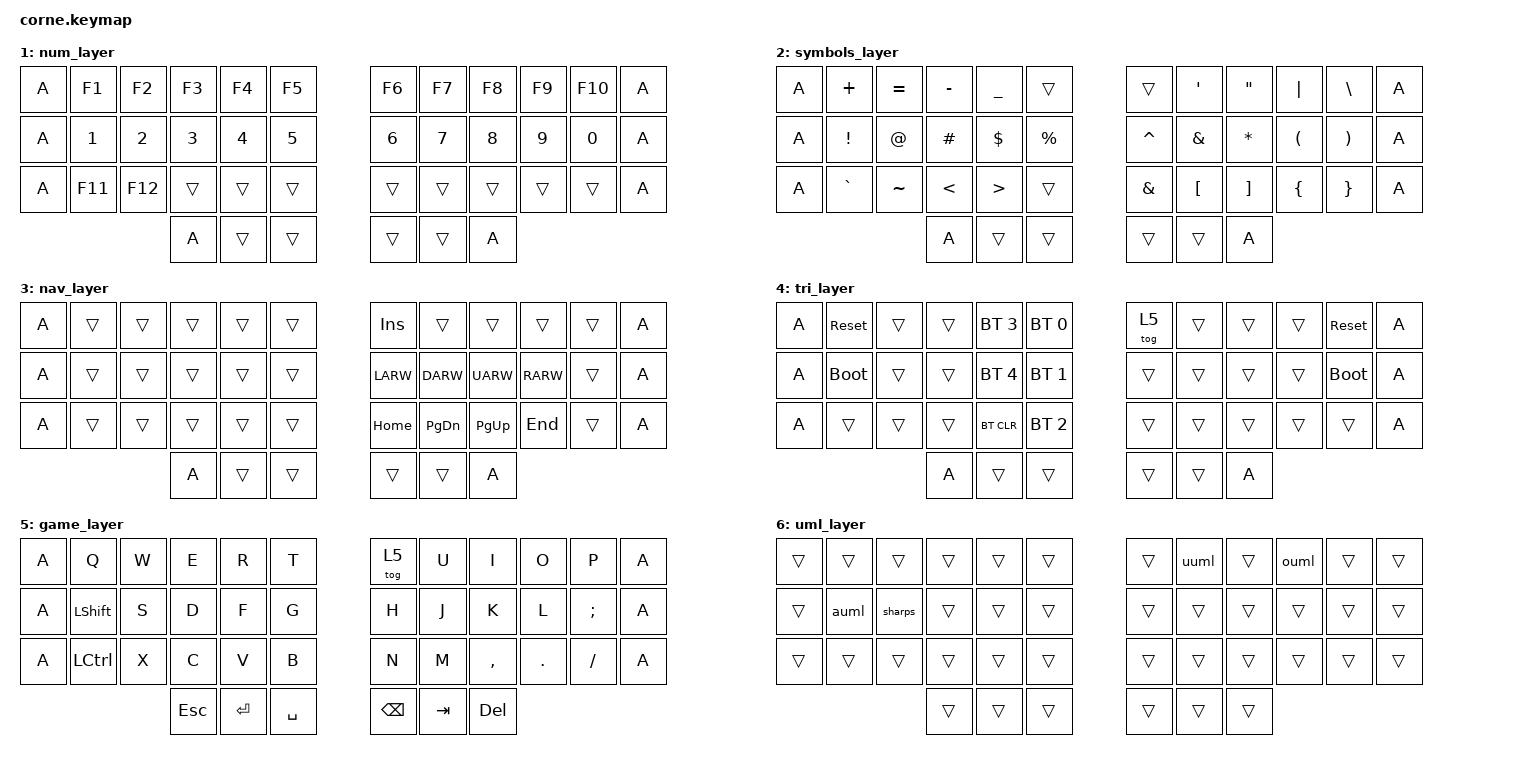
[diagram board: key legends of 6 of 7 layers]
// Copyright (c) 2022 The ZMK Contributors
// SPDX-License-Identifier: MIT

#include <behaviors.dtsi>
#include <dt-bindings/zmk/keys.h>
#include <dt-bindings/zmk/bt.h>

// Home row mods macro
#define HRML(k1,k2,k3,k4) &ht LSHFT k1  &ht LCTRL k2  &ht LGUI k3  &ht LALT k4
#define HRMR(k1,k2,k3,k4) &ht RALT k1  &ht RGUI k2  &ht RCTRL k3  &ht RSHFT k4

// combo macro
#define COMBO(name, pos, bind) name { timeout-ms = <30>; key-positions = pos ; bindings = bind ; };

/ {
    macros {
        auml: auml {
            compatible = "zmk,behavior-macro";
            #binding-cells = <0>;
            bindings = <&macro_tap &kp RALT &kp A &kp DQT> ;
        };
        uuml: uuml {
            compatible = "zmk,behavior-macro";
            #binding-cells = <0>;
            bindings = <&macro_tap &kp RALT &kp U &kp DQT> ;
        };
        ouml: ouml {
            compatible = "zmk,behavior-macro";
            #binding-cells = <0>;
            bindings = <&macro_tap &kp RALT &kp O &kp DQT> ;
        };
        sharps: sharps {
            compatible = "zmk,behavior-macro";
            #binding-cells = <0>;
            bindings = <&macro_tap &kp RALT &kp S &kp S> ;
        };
    };

    behaviors {
        ht: hold_tap {
            label = "hold_tap";
            compatible = "zmk,behavior-hold-tap";
            #binding-cells = <2>;
            flavor = "balanced";
            tapping-term-ms = <220>;
            quick-tap-ms = <150>;
            #global-quick-tap;
            bindings = <&kp>, <&kp>;
        };
    };

    conditional_layers {
        compatible = "zmk,conditional-layers";
        tri_layer {
            if-layers = <1 2>;
            then-layer = <4>;
        };
    };

    combos {
        compatible = "zmk,combos";

        COMBO(combo_caps,  <13 22>, <&caps_word>)

        COMBO(combo_lt,    <2  3 >, <&kp LT>)
        COMBO(combo_lbkt,  <3  4 >, <&kp LBKT>)
        COMBO(combo_rbkt,  <7  8 >, <&kp RBKT>)
        COMBO(combo_gt,    <8  9 >, <&kp GT>)
        COMBO(combo_lbrc,  <14 15>, <&kp LBRC>)
        COMBO(combo_lpar,  <15 16>, <&kp LPAR>)
        COMBO(combo_rpar,  <19 20>, <&kp RPAR>)
        COMBO(combo_rbrc,  <20 21>, <&kp RBRC>)

    };

    keymap {
        compatible = "zmk,keymap";
        default_layer {
            bindings = <
        //╭────1─────┬────2─────┬────3─────┬────4─────┬────5─────╮   ╭────6─────┬────7─────┬────8─────┬────9─────┬────10────╮
        //│  Q       │  W       │  E       │  R       │  T       │   │  Y       │  U       │  I       │  O       │  P       │
&kp A       &kp Q      &kp W      &kp E      &kp R      &kp T          &kp Y      &kp U      &kp I      &kp O      &kp P        &kp A
        //├───13─────┼────14────┼────15────┼────16────┼────17────┤   ├────18────┼────19────┼────20────┼────21────┼────22────┤
        //│  A       │  S       │  D       │  F       │  G       │   │  H       │  J       │  K       │  L       │  : ;     │
&kp A       HRML(A,        S,         D,         F)     &kp G          &kp H      HRMR(J,        K,         L,      SEMI)        &kp A
        //├────25────┼────26────┼────27────┼────28────┼────29────┤   ├────30────┼────31────┼────32────┼────33────┼────34────┤
        //│  Z       │  X       │  C       │  V       │  B       │   │  N       │  M       │ , <      │ . >      │ / ?      │
&kp A       &kp Z      &kp X      &kp C      &kp V      &kp B          &kp N      &kp M      &kp COMMA  &kp DOT    &kp FSLH        &kp A
        //╰──────────┴──────────┴──────────┼──────────┼──────────┤   ├──────────┼──────────┼──────────┴──────────┴──────────╯
                                  &kp ESC  &lt 3 ENTER &lt 2 SPACE     &lt 1 BSPC   &lt 6 TAB  &kp DEL
        //                      ╰──────────┴──────────┴──────────╯   ╰──────────┴──────────┴──────────╯
            >;
        };

        num_layer {
            bindings = <
        //╭──────────┬──────────┬──────────┬──────────┬──────────╮   ╭──────────┬──────────┬──────────┬──────────┬──────────╮
        //│ F1       │  F2      │  F3      │  F4      │ F5       │   │ F6       │ F7       │ F8       │ F9       │  F10     │
&kp A       &kp F1     &kp F2     &kp F3     &kp F4     &kp F5         &kp F6     &kp F7     &kp F8     &kp F9      &kp F10        &kp A
        //├──────────┼──────────┼──────────┼──────────┼──────────┤   ├──────────┼──────────┼──────────┼──────────┼──────────┤
        //│ 1        │  2       │  3       │  4       │ 5        │   │ 6        │ 7        │ 8        │ 9        │  0       │
&kp A       &kp N1      &kp N2     &kp N3     &kp N4     &kp N5        &kp N6     &kp N7     &kp N8     &kp N9      &kp N0        &kp A
        //├──────────┼──────────┼──────────┼──────────┼──────────┤   ├──────────┼──────────┼──────────┼──────────┼──────────┤
        //│ F11      │  F12     │  caps    │          │          │   │          │          │          │          │          │
&kp A      &kp F11    &kp F12    &trans      &trans     &trans         &trans     &trans     &trans     &trans     &trans        &kp A
        //╰──────────┴──────────┴──────────┼──────────┼──────────┤   ├──────────┼──────────┼──────────┴──────────┴──────────╯
&kp A                                        &trans     &trans         &trans     &trans        &kp A
        //                                 ╰──────────┴──────────╯   ╰──────────┴──────────╯
            >;
        };


         symbols_layer {
            bindings = <
        //╭──────────┬──────────┬──────────┬──────────┬──────────╮   ╭──────────┬──────────┬──────────┬──────────┬──────────╮
        //│ +        │  =       │  -       │  _       │          │   │          │  '       │  "       │  |       │  \       │
&kp A       &kp PLUS   &kp EQUAL  &kp MINUS  &kp UNDER  &trans         &trans     &kp SQT    &kp DQT    &kp PIPE   &kp BSLH        &kp A
        //├──────────┼──────────┼──────────┼──────────┼──────────┤   ├──────────┼──────────┼──────────┼──────────┼──────────┤
        //│  !       │  @       │  #       │  $       │  %       │   │  ^       │  &       │  *       │  (       │  )       │
&kp A       &kp EXCL   &kp AT     &kp HASH   &kp DLLR   &kp PRCNT      &kp CARET  &kp AMPS  &kp ASTRK  &kp LPAR   &kp RPAR        &kp A
        //├──────────┼──────────┼──────────┼──────────┼──────────┤   ├──────────┼──────────┼──────────┼──────────┼──────────┤
        //│ `        │ ~        │          │          │          │   │          │  [       │  ]       │  {       │ }        │
&kp A       &kp GRAVE  &kp TILDE  &kp LT     &kp GT     &trans         &kp AMPS   &kp LBKT  &kp RBKT   &kp LBRC   &kp RBRC        &kp A
        //╰──────────┴──────────┴──────────┼──────────┼──────────┤   ├──────────┼──────────┼──────────┴──────────┴──────────╯
&kp A                                        &trans     &trans         &trans     &trans        &kp A
        //                                 ╰──────────┴──────────╯   ╰──────────┴──────────╯
            >;
        };

        nav_layer {
            bindings = <
        //╭──────────┬──────────┬──────────┬──────────┬──────────╮   ╭──────────┬──────────┬──────────┬──────────┬──────────╮
        //│          │          │          │          │          │   │          │          │          │          │          │
&kp A       &trans     &trans     &trans     &trans     &trans         &kp INS    &trans     &trans     &trans     &trans        &kp A
        //├──────────┼──────────┼──────────┼──────────┼──────────┤   ├──────────┼──────────┼──────────┼──────────┼──────────┤
        //│          │          │          │          │          │   │ up       │ down     │ up       │ right    │          │
&kp A       &trans      &trans     &trans     &trans     &trans        &kp LARW   &kp DARW   &kp UARW   &kp RARW   &trans        &kp A
        //├──────────┼──────────┼──────────┼──────────┼──────────┤   ├──────────┼──────────┼──────────┼──────────┼──────────┤
        //│ CAPS     │          │          │          │          │   │          │          │          │          │          │
&kp A      &trans      &trans     &trans     &trans     &trans         &kp HOME   &kp PG_DN  &kp PG_UP  &kp END    &trans        &kp A
        //╰──────────┴──────────┴──────────┼──────────┼──────────┤   ├──────────┼──────────┼──────────┴──────────┴──────────╯
&kp A                                        &trans     &trans         &trans     &trans        &kp A
        //                                 ╰──────────┴──────────╯   ╰──────────┴──────────╯
            >;
        };



        tri_layer {
            bindings = <
        //╭──────────┬──────────┬──────────┬──────────┬──────────╮   ╭──────────┬──────────┬──────────┬──────────┬──────────╮
        //│ RESET    │          │          │          │PROFILE 0 │   │          │          │          │          │  RESET   │
&kp A      &sys_reset  &trans     &trans  &bt BT_SEL 3 &bt BT_SEL 0    &tog 5     &trans     &trans     &trans    &sys_reset        &kp A
        //├──────────┼──────────┼──────────┼──────────┼──────────┤   ├──────────┼──────────┼──────────┼──────────┼──────────┤
        //│BOOTLOADER│          │          │          │PROFILE 1 │   │          │          │          │          │BOOTLOADER│
&kp A     &bootloader  &trans     &trans  &bt BT_SEL 4 &bt BT_SEL 1    &trans     &trans     &trans     &trans    &bootloader        &kp A
        //├──────────┼──────────┼──────────┼──────────┼──────────┤   ├──────────┼──────────┼──────────┼──────────┼──────────┤
        //│          │          │          │ CLEAR BT │PROFILE 2 │   │          │          │          │          │          │
&kp A       &trans     &trans     &trans    &bt BT_CLR &bt BT_SEL 2    &trans     &trans     &trans     &trans     &trans        &kp A
        //╰──────────┴──────────┴──────────┼──────────┼──────────┤   ├──────────┼──────────┼──────────┴──────────┴──────────╯
&kp A                                        &trans     &trans         &trans     &trans        &kp A
        //                                 ╰──────────┴──────────╯   ╰──────────┴──────────╯
            >;
        };

        game_layer {
            bindings = <
        //╭──────────┬──────────┬──────────┬──────────┬──────────╮   ╭──────────┬──────────┬──────────┬──────────┬──────────╮
        //│  Q       │  W       │  E       │  R       │  T       │   │  Y       │  U       │  I       │  O       │  P       │
&kp A       &kp Q      &kp W      &kp E      &kp R      &kp T          &tog 5      &kp U      &kp I      &kp O      &kp P        &kp A
        //├──────────┼──────────┼──────────┼──────────┼──────────┤   ├──────────┼──────────┼──────────┼──────────┼──────────┤
        //│  A       │  S       │  D       │  F       │  G       │   │  H       │  J       │  K       │  L       │  : ;     │
&kp A       &kp LSHFT     &kp S      &kp D      &kp F      &kp G          &kp H       &kp J     &kp K      &kp L   &kp SEMI         &kp A
        //├──────────┼──────────┼──────────┼──────────┼──────────┤   ├──────────┼──────────┼──────────┼──────────┼──────────┤
        //│  Z       │  X       │  C       │  V       │  B       │   │  N       │  M       │ , <      │ . >      │ / ?      │
&kp A       &kp LCTRL      &kp X      &kp C      &kp V      &kp B          &kp N      &kp M      &kp COMMA  &kp DOT    &kp FSLH        &kp A
        //╰──────────┴──────────┴──────────┼──────────┼──────────┤   ├──────────┼──────────┼──────────┴──────────┴──────────╯
                                  &kp ESC  &kp ENTER &kp SPACE         &kp BSPC   &kp TAB  &kp DEL
        //                      ╰──────────┴──────────┴──────────╯   ╰──────────┴──────────┴──────────╯
            >;
        };

        uml_layer {
            bindings = <
        //╭──────────┬──────────┬──────────┬──────────┬──────────╮   ╭──────────┬──────────┬──────────┬──────────┬──────────╮
        //│  Q       │  W       │  E       │  R       │  T       │   │  Y       │  U       │  I       │  O       │  P       │
&trans      &trans     &trans     &trans     &trans     &trans         &trans      &uuml     &trans     &ouml     &trans       &trans
        //├──────────┼──────────┼──────────┼──────────┼──────────┤   ├──────────┼──────────┼──────────┼──────────┼──────────┤
        //│  A       │  S       │  D       │  F       │  G       │   │  H       │  J       │  K       │  L       │  : ;     │
&trans      &auml     &sharps     &trans     &trans     &trans         &trans      &trans     &trans     &trans     &trans       &trans
        //├──────────┼──────────┼──────────┼──────────┼──────────┤   ├──────────┼──────────┼──────────┼──────────┼──────────┤
        //│  Z       │  X       │  C       │  V       │  B       │   │  N       │  M       │ , <      │ . >      │ / ?      │
&trans      &trans     &trans     &trans     &trans     &trans         &trans      &trans     &trans     &trans     &trans       &trans
        //╰──────────┴──────────┴──────────┼──────────┼──────────┤   ├──────────┼──────────┼──────────┴──────────┴──────────╯
                                  &trans   &trans    &trans            &trans     &trans   &trans
        //                      ╰──────────┴──────────┴──────────╯   ╰──────────┴──────────┴──────────╯
            >;
        };
    };
};
